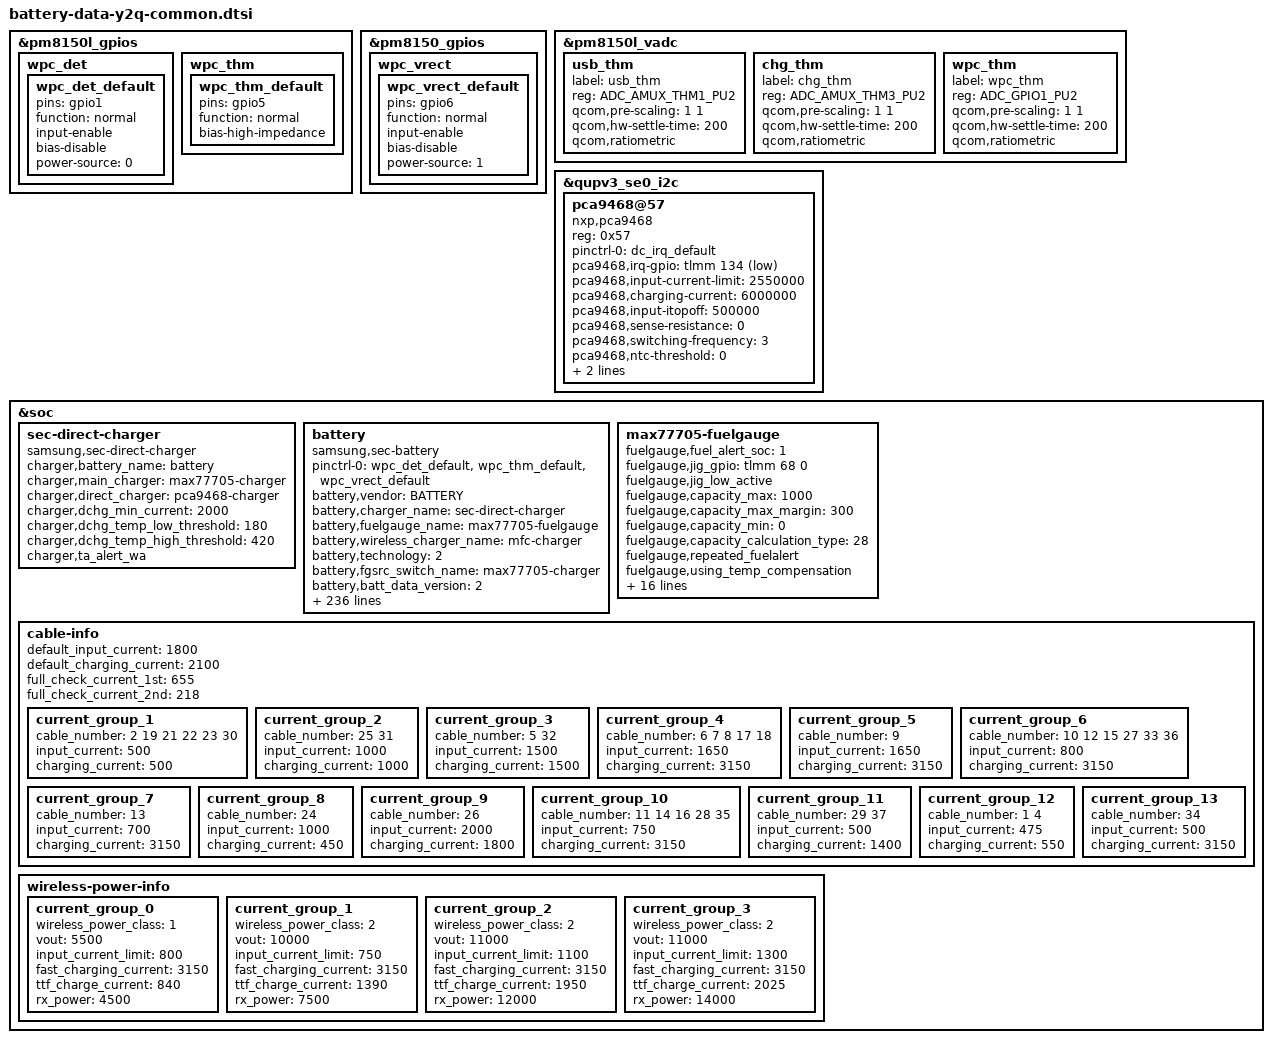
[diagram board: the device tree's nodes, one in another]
/* Copyright (c) 2014, The Linux Foundation. All rights reserved.
 *
 * This program is free software; you can redistribute it and/or modify
 * it under the terms of the GNU General Public License version 2 and
 * only version 2 as published by the Free Software Foundation.
 *
 * This program is distributed in the hope that it will be useful,
 * but WITHOUT ANY WARRANTY; without even the implied warranty of
 * MERCHANTABILITY or FITNESS FOR A PARTICULAR PURPOSE.  See the
 * GNU General Public License for more details.
 */

#include "battery-rx-data-y2q-idt.dtsi"

&pm8150l_gpios {
	wpc_det { /* WPC_DET */
		wpc_det_default: wpc_det_default {
			pins = "gpio1";
			function = "normal";
			input-enable;
			bias-disable;
			power-source = <0>;
		};
	};
	wpc_thm { /* GPIO_05 */
		wpc_thm_default: wpc_thm_default {
			pins = "gpio5";
			function = "normal";
			bias-high-impedance;
		};
	};
};

&pm8150_gpios {
    wpc_vrect { /* VRECT_INT */
        wpc_vrect_default: wpc_vrect_default {
            pins = "gpio6";
            function = "normal";
            input-enable;
            bias-disable;
            power-source = <1>;
        };
    };
};

&pm8150l_vadc {
	usb_thm { /* AMUX_1 */
		label = "usb_thm";
		reg = <ADC_AMUX_THM1_PU2>;
		qcom,pre-scaling = <1 1>;
		qcom,hw-settle-time = <200>;
		qcom,ratiometric;
	};
	chg_thm { /* AMUX_3 */
		label = "chg_thm";
		reg = <ADC_AMUX_THM3_PU2>;
		qcom,pre-scaling = <1 1>;
		qcom,hw-settle-time = <200>;
		qcom,ratiometric;
	};
	wpc_thm { /* GPIO_05 */
		label = "wpc_thm";
		reg = <ADC_GPIO1_PU2>;
		qcom,pre-scaling = <1 1>;
		qcom,hw-settle-time = <200>;
		qcom,ratiometric;
	};
};

&qupv3_se0_i2c {
	status = "okay";

	pca9468@57 {
		compatible = "nxp,pca9468";
		reg = <0x57>;
		pinctrl-names = "default";
		pinctrl-0 = <&dc_irq_default>;

		pca9468,irq-gpio = <&tlmm 134 GPIO_ACTIVE_LOW>; /* DC_IRQ */
		pca9468,input-current-limit = <2550000>; /* 2.55A */
		pca9468,charging-current = <6000000>; /* 6A */
		pca9468,input-itopoff = <500000>; /* 500mA */
		pca9468,sense-resistance = <0>; /* 5mOhm */
		pca9468,switching-frequency = <3>; /* 980KHz */
		pca9468,ntc-threshold = <0>; /* disable */
		pca9468,chg_gpio_en = <&tlmm 173 0>; /* DC_CPEN */
		pca9468,ta-mode = <1>; /* 2:1 charging mode */
	};
};

&soc {
	sec-direct-charger {
		status = "okay";
		compatible = "samsung,sec-direct-charger";

		charger,battery_name = "battery";
		charger,main_charger = "max77705-charger";
		charger,direct_charger = "pca9468-charger";

		charger,dchg_min_current = <2000>;
		charger,dchg_temp_low_threshold = <180>;
		charger,dchg_temp_high_threshold = <420>;

		charger,ta_alert_wa;
	};

	battery {
		status = "okay";
		compatible = "samsung,sec-battery";
		pinctrl-names = "default";
		pinctrl-0 = <&wpc_det_default &wpc_thm_default &wpc_vrect_default>;
		battery,vendor = "BATTERY";
		battery,charger_name = "sec-direct-charger";
		battery,fuelgauge_name = "max77705-fuelgauge";
		battery,wireless_charger_name = "mfc-charger";
		battery,technology = <2>; /* POWER_SUPPLY_TECHNOLOGY_LION */
		battery,fgsrc_switch_name = "max77705-charger"; /* Fuelgauge voltage source */

		battery,batt_data_version = <2>;

		battery,chip_vendor = "QCOM";
		battery,temp_adc_type = <1>; /* SEC_BATTERY_ADC_TYPE_AP */

		battery,temp_check_type = <1>; /* SEC_BATTERY_TEMP_CHECK_ADC */
		battery,usb_temp_check_type = <1>;
		battery,chg_temp_check_type = <1>;
		battery,wpc_temp_check_type = <1>;
		battery,dchg_temp_check_type = <1>;

		battery,thermal_source = <2>; /* SEC_BATTERY_THERMAL_SOURCE_ADC */
		battery,usb_thermal_source = <2>; /* SEC_BATTERY_THERMAL_SOURCE_ADC */
		battery,chg_thermal_source = <2>; /* SEC_BATTERY_THERMAL_SOURCE_ADC */
		battery,wpc_thermal_source = <2>; /* SEC_BATTERY_THERMAL_SOURCE_ADC */
		battery,dchg_thermal_source = <3>; /* SEC_BATTERY_THERMAL_SOURCE_CHG_ADC */

		battery,polling_time = <10 30 30 30 3600>;

		battery,temp_table_adc = <138199 161533 186995 214402 249134
						288847 341868 396892 460726 535005
						615065 704397 800865 899552 1008268
						1121431 1232583 1338104 1426520 1514907
						1587874 1647527 1699531>;
		battery,temp_table_data = <900 850 800 750 700
						650 600 550 500 450
						400 350 300 250 200
						150 100 50 0 (-50)
						(-100) (-150) (-200)>;

		battery,usb_temp_table_adc = <239676 280124 326167 374869 432677
						499761 573557 652248 738271 833167
						926469 1023081 1121431 1216356 1309450
						1399286 1479339 1549891 1607057 1657965
						1699401 1731119 1757114>;
		battery,usb_temp_table_data = <900 850 800 750 700
						650 600 550 500 450
						400 350 300 250 200
						150 100 50 0 (-50)
						(-100) (-150) (-200)>;

		battery,chg_temp_table_adc = <111317 134709 158549 185834 216586
						253719 307006 362355 426347 494585
						582842 670883 766096 866897 971806
						1080427 1188285 1297663 1388249 1478597
						1559760 1617754 1672663>;
		battery,chg_temp_table_data = <900 850 800 750 700
						650 600 550 500 450
						400 350 300 250 200
						150 100 50 0 (-50)
						(-100) (-150) (-200)>;

		battery,wpc_temp_table_adc = <138199 161533 186995 214402 249134
						288847 341868 396892 460726 535005
						615065 704397 800865 899552 1008268
						1121431 1232583 1338104 1426520 1514907
						1587874 1647527 1699531>;
		battery,wpc_temp_table_data = <900 850 800 750 700
						650 600 550 500 450
						400 350 300 250 200
						150 100 50 0 (-50)
						(-100) (-150) (-200)>;

		battery,dchg_temp_table_adc = <98532 119646 143106 170476 195500
						229908 281520 333914 394910 459034
						542708 624036 722568 821882 920414
						1024420 1120606 1229304 1320798 1406818
						1493620 1546014 1599190>;
		battery,dchg_temp_table_data = <900 850 800 750 700
						650 600 550 500 450
						400 350 300 250 200
						150 100 50 0 (-50)
						(-100) (-150) (-200)>;

		battery,wireless_cc_cv = <85>;
		battery,wpc_det = <&pm8150l_gpios 1 GPIO_ACTIVE_HIGH>; /* WPC_DET */
		battery,wpc_en = <&tlmm 127 0>; /* WPC_EN */
		battery,mst_pwr_en = <&tlmm 151 0>; /* MST_PWR_EN */
		battery,adc_check_count = <5>;

		battery,cable_check_type = <4>; /* SEC_BATTERY_CABLE_CHECK_PSY */
		battery,cable_source_type = <1>; /* SEC_BATTERY_CABLE_SOURCE_EXTERNAL */
		battery,polling_type = <1>; /* SEC_BATTERY_MONITOR_ALARM */
		battery,monitor_initial_count = <0>;

		battery,battery_check_type = <0>; /* SEC_BATTERY_CHECK_NONE */
		battery,check_count = <0>;
		battery,check_adc_max = <1440>;
		battery,check_adc_min = <0>;

		battery,ovp_uvlo_check_type = <3>; /* SEC_BATTERY_OVP_UVLO_CHGPOLLING */

		battery,temp_check_count = <1>;
		battery,temp_highlimit_threshold_event = <700>;
		battery,temp_highlimit_recovery_event = <680>;
		battery,temp_high_threshold_event = <500>;
		battery,temp_high_recovery_event = <480>;
		battery,temp_low_threshold_event = <0>;
		battery,temp_low_recovery_event = <20>;
		battery,temp_highlimit_threshold_normal = <700>;
		battery,temp_highlimit_recovery_normal = <680>;
		battery,temp_high_threshold_normal = <500>;
		battery,temp_high_recovery_normal = <480>;
		battery,temp_low_threshold_normal = <0>;
		battery,temp_low_recovery_normal = <20>;
		battery,temp_highlimit_threshold_lpm = <700>;
		battery,temp_highlimit_recovery_lpm = <680>;
		battery,temp_high_threshold_lpm = <500>;
		battery,temp_high_recovery_lpm = <480>;
		battery,temp_low_threshold_lpm = <0>;
		battery,temp_low_recovery_lpm = <20>;
		battery,wpc_high_threshold_normal = <450>;
		battery,wpc_high_recovery_normal = <430>;
		battery,wpc_low_threshold_normal = <0>;
		battery,wpc_low_recovery_normal = <20>;
		battery,tx_high_threshold = <450>;
		battery,tx_high_recovery = <400>;
		battery,tx_low_threshold = <0>;
		battery,tx_low_recovery = <50>;
		battery,full_check_type = <2>; /* SEC_BATTERY_FULLCHARGED_FG_CURRENT */
		battery,full_check_type_2nd = <2>; /* SEC_BATTERY_FULLCHARGED_FG_CURRENT */
		battery,full_check_count = <1>;
		battery,chg_gpio_full_check = <0>;
		battery,chg_polarity_full_check = <1>;

		battery,chg_high_temp = <450>;
		battery,chg_high_temp_recovery = <430>;
		battery,dchg_high_temp = <500>;
		battery,dchg_high_temp_recovery = <440>;
		battery,dchg_high_batt_temp = <400>;
		battery,dchg_high_batt_temp_recovery = <380>;
		battery,chg_input_limit_current = <1000>;
		battery,chg_charging_limit_current = <1900>;
		battery,dchg_input_limit_current = <1000>;
		battery,dchg_charging_limit_current = <2000>;

		battery,charging_limit_by_tx_check = <1>;
		battery,charging_limit_current_by_tx = <1100>;

		battery,wpc_temp_control_source = <1>; /* TEMP_CONTROL_SOURCE_BAT_THM = WPC_THM */
		battery,wpc_high_temp = <400>;
		battery,wpc_high_temp_recovery = <380>;
		battery,wpc_input_limit_current = <600>;
		battery,wpc_charging_limit_current = <3150>;
		battery,wpc_temp_lcd_on_control_source = <1>; /* TEMP_CONTROL_SOURCE_BAT_THM = WPC_THM */
		battery,wpc_lcd_on_high_temp = <400>;
		battery,wpc_lcd_on_high_temp_rec = <380>;
		battery,wpc_lcd_on_input_limit_current = <450>;

		battery,wpc_store_high_temp = <360>;
		battery,wpc_store_high_temp_recovery = <340>;
		battery,wpc_store_charging_limit_current = <400>;
		battery,wpc_store_lcd_on_high_temp = <360>;
		battery,wpc_store_lcd_on_high_temp_rec = <300>;
		battery,wpc_store_lcd_on_charging_limit_current = <400>;
		battery,store_mode_buckoff;

		battery,ta_alert_wa;

		battery,sleep_mode_limit_current = <800>;
		battery,wc_full_input_limit_current = <100>;

		battery,mix_high_temp = <420>;
		battery,mix_high_chg_temp = <500>;
		battery,mix_high_temp_recovery = <390>;

		/* SEC_BATTERY_FULL_CONDITION_NOTIMEFULL | SEC_BATTERY_FULL_CONDITION_VCELL */
		battery,full_condition_type = <9>;
		battery,full_condition_soc = <93>;
		battery,full_condition_vcell = <4330>;

		battery,recharge_check_count = <1>;
		battery,recharge_condition_type = <4>; /* SEC_BATTERY_RECHARGE_CONDITION_VCELL */
		battery,recharge_condition_soc = <98>;
		battery,recharge_condition_vcell = <4310>;

		battery,charging_total_time = <14400>;
		battery,hv_charging_total_time = <10800>;
		battery,normal_charging_total_time = <18000>;
		battery,usb_charging_total_time = <36000>;
		battery,recharging_total_time = <5400>;
		battery,charging_reset_time = <0>;

		battery,chg_float_voltage = <4380>;
		battery,chg_ocp_current = <6200>;
		battery,chg_ocp_dtc = <100>;

		battery,pre_afc_work_delay = <2000>;
		battery,pre_wc_afc_work_delay = <4000>;
		battery,pre_afc_input_current = <500>;
		battery,pre_wc_afc_input_current = <500>;
		battery,prepare_ta_delay = <0>; /* msec */

		battery,swelling_high_temp_block = <420>;
		battery,swelling_high_temp_recov = <400>;
		battery,swelling_wc_high_temp_block = <420>;
		battery,swelling_wc_high_temp_recov = <400>;
		battery,swelling_low_temp_block_1st = <150>;
		battery,swelling_low_temp_recov_1st = <170>;
		battery,swelling_low_temp_block_2nd = <50>;
		battery,swelling_low_temp_recov_2nd = <70>;
		battery,swelling_low_temp_3rd_ctrl;
		battery,swelling_low_temp_block_3rd = <180>;
		battery,swelling_low_temp_recov_3rd = <200>;

		battery,swelling_low_temp_current = <1000>;	/* 0.24C */
		battery,swelling_low_temp_current_2nd = <400>;	/* 0.1C */
		battery,swelling_low_temp_current_3rd = <3100>;	/* 0.72C */
		battery,swelling_low_temp_topoff = <218>;	/* 0.05C */
		battery,swelling_high_temp_current = <1550>;	/* 0.36C */
		battery,swelling_high_temp_topoff = <218>;	/* 0.05C */
		battery,swelling_wc_high_temp_current = <1000>;	/* 0.24C */
		battery,swelling_wc_low_temp_current = <1000>;	/* 0.24C */
		battery,swelling_wc_low_temp_current_2nd = <400>;	/* 0.1C */
		battery,swelling_wc_low_temp_current_3rd = <3100>;	/* 0.72C */

		battery,swelling_drop_float_voltage = <4150>;
		battery,swelling_high_rechg_voltage = <4000>;
		battery,swelling_low_rechg_thr = <180>;

		battery,siop_input_limit_current = <1200>;
		battery,siop_charging_limit_current = <1800>;
		battery,siop_hv_input_limit_current = <700>;
		battery,siop_hv_input_limit_current_2nd = <450>;
		battery,siop_hv_charging_limit_current = <1000>;
		battery,siop_apdo_input_limit_current = <1000>;
		battery,siop_apdo_charging_limit_current = <2000>;

		battery,siop_wireless_input_limit_current = <700>;
		battery,siop_wireless_charging_limit_current = <700>;
		battery,siop_hv_wireless_input_limit_current = <700>;
		battery,siop_hv_wireless_charging_limit_current = <700>;
		battery,siop_store_hv_wireless_input_limit_current = <450>;

		battery,wireless_otg_input_current = <900>;

		battery,ttf_hv_charge_current = <2625>;
		battery,ttf_hv_wireless_charge_current = <1390>;
		battery,ttf_wireless_charge_current = <840>;
		battery,ttf_dc25_charge_current = <4000>;

		battery,rp_current_rp1 = <500>;
		battery,rp_current_rp2 = <1500>;
		battery,rp_current_rp3 = <3000>;
		battery,rp_current_rdu_rp3 = <2100>;
		battery,rp_current_abnormal_rp3 = <1800>;

		battery,pd_charging_charge_power = <15000>;
		battery,max_charging_current = <3150>;
		battery,max_charging_charge_power = <25000>; /* 25W */

		/* cycle, chg_float_voltage, recharge_condition_vcell, full_condition_vcell, full_condition_soc, step charging condition */
		battery,age_data = <0 4380 4310 4330 93
				300 4360 4290 4310 92
				400 4340 4270 4290 91
				700 4320 4250 4270 90
				1000 4270 4200 4220 89>;

		battery,health_condition = <
			/* CYCLE ASOC */
			900 75	/* GOOD */
			1200 65 /* NORMAL */
			1500 55 /* AGED */
			>;

		/* step charging option */
		battery,step_charging_type = <0>;

		/* direct step charging option */
		battery,dc_step_chg_type = <0x6B>;
		battery,dc_step_chg_charge_power = <22000>;
		battery,dc_step_chg_step = <3>;
		battery,dc_step_chg_cond_vol = <4125 4250 4380>; /*<25w 3step> STEP_CHARGING_CONDITION_VOLTAGE */ 
		battery,dc_step_chg_cond_iin = <2045 1835 0>; /* <25w 3step> STEP_CHARGING_CONDITION_INPUT_CURRENT */
		battery,dc_step_chg_iin_check_cnt = <3>;
		battery,dc_step_chg_cond_soc = <35 60 100
										35 60 100
										35 60 100
										35 60 100
										35 60 100>; /* <25w 3step> STEP_CHARGING_CONDITION_SOC */
		battery,dc_step_chg_val_vfloat = <4125 4250 4380>; /* <25w 3step> STEP_CHARGING_CONDITION_FLOAT_VOLTAGE */
		battery,dc_step_chg_val_iout = <5290 4090 3670>; /* <25w 3step> */


		battery,snkcap_data = /bits/ 8 <0x04 0x2C 0x91 0x01 0x36 0xC8 0xD0 0x02 0x00 0xC8 0x90
								0x41 0x8B 0x35 0x21 0xDC 0xC0>;


		battery,max_input_voltage = <9000>; /* mV */
		battery,max_input_current = <3000>; /* mA */

		battery,enable_sysovlo_irq;
		battery,enable_noise_wa;
		battery,dis_auto_shipmode_temp_ctrl;

		battery,standard_curr = <3150>;
		battery,expired_time = <10800>;
		battery,recharging_expired_time = <5400>;

		battery,battery_full_capacity = <4500>;
		battery,cisd_max_voltage_thr = <4430>; /* batttery ovp dettection voltage */
		battery,cisd_alg_index = <8>;
		battery,ignore_cisd_index = <0 0>;
		battery,ignore_cisd_index_d = <0 80>; /* Do not use AFC_FAIL_PER_DAY to DROP_VALUE_PER_DAY */ 

		battery,tx_stop_capacity = <30>;
		battery,tx_minduty_default = <20>;
		battery,tx_minduty_5V = <50>;

		battery,tx_uno_vout = <5>; /* WC_TX_VOUT_7_5V */
		battery,tx_gear_vout = <0>; /* WC_TX_VOUT_5_0V */
		battery,tx_uno_iout = <1500>;
		battery,tx_mfc_iout_gear = <1500>;
		battery,tx_mfc_iout_phone = <1100>;
		battery,tx_mfc_iout_phone_5v = <300>;
		battery,tx_mfc_iout_lcd_on = <900>;

		battery,batt_temp_adj_gap_inc = <100>;
		battery,batt_temp_adj_gap_dec = <100>;
		/* battery,fake_capacity; */

		battery,support_unknown_wpcthm;

		io-channels = <&pm8150l_vadc ADC_GPIO1_PU2>, <&pm8150l_vadc ADC_AMUX_THM3_PU2>, <&pm8150l_vadc ADC_GPIO1_PU2>, <&pm8150l_vadc ADC_AMUX_THM1_PU2>;
		io-channel-names = "adc-temp", "adc-chg-temp", "adc-wpc-temp", "adc-usb-temp";
	};

	max77705-fuelgauge {
		/* for 4500mAh battery */
		status = "okay";
		fuelgauge,fuel_alert_soc = <1>;
		fuelgauge,jig_gpio = <&tlmm 68 0>; /* IFC_SENSE_INT_AP */
		fuelgauge,jig_low_active;
		fuelgauge,capacity_max = <1000>;
		fuelgauge,capacity_max_margin = <300>;
		fuelgauge,capacity_min = <0>;
		fuelgauge,capacity_calculation_type = <28>;
		fuelgauge,repeated_fuelalert;
		fuelgauge,using_temp_compensation;
		fuelgauge,low_temp_limit = <100>;
		fuelgauge,using_hw_vempty;
		fuelgauge,v_empty = <0xA7E2>; /* Empty: 3350mV, Recover: 3920mV */
		fuelgauge,v_empty_origin = <0x7D54>; /* Empty: 2500mV, Recover: 3360mV */
		fuelgauge,sw_v_empty_voltage = <3200>;
		fuelgauge,sw_v_empty_voltage_cisd = <3100>;
		fuelgauge,sw_v_empty_recover_voltage = <3480>;
		fuelgauge,fg_resistor = <2>;
		fuelgauge,capacity = <0x0FEF>; /* capacity = fullcapnom = DesignCap */
		fuelgauge,fg_reset_wa_data = <0x0FEF 0x3200 0x03FB 0x0034 0x2534>; /* fullcapnom(=capacity), dPacc, dQacc,  rcomp0, tempco */
		fuelgauge,discharge_temp_threshold = <600>;
		fuelgauge,discharge_volt_threshold = <4200>;
		fuelgauge,ttf_capacity = <3625>;
		fuelgauge,cv_data = <
			3733	840	1462
			3616	847	1432
			3575	849	1421
			3452	853	1401
			3342	860	1370
			3228	864	1350
			3133	866	1340
			3019	874	1299
			2929	879	1268
			2843	883	1247
			2754	887	1227
			2625	895	1176
			2531	898	1155
			2410	905	1114
			2348	908	1094
			2214	915	1043
			2103	920	1002
			2019	924	971
			1911	930	920
			1834	933	899
			1722	942	817
			1649	946	776
			1532	950	735
			1410	958	643
			1338	960	623
			1213	969	510
			1105	975	428
			1010	983	305
			955	988	223
			881	990	123
			864	996	113
			761	1000	103
			710	1000	51
			668	1000	0
		>;
	};

/* sec_battery_cable
 *   0	UNKNOWN,
 *   1	NONE,
 *   2	PREPARE_TA,
 *   3	TA,
 *   4	USB,
 *   5	USB_CDP,
 *   6	9V_TA,
 *   7	9V_ERR,
 *   8	9V_UNKNOWN,
 *   9	12V_TA,
 *  10	WIRELESS,
 *  11	HV_WIRELESS,
 *  12	PMA_WIRELESS,
 *  13	WIRELESS_PACK,
 *  14	CABLE_WIRELESS_HV_PACK,
 *  15	WIRELESS_STAND,
 *  16	WIRELESS_HV_STAND,
 *  17	QC20,
 *  18	QC30,
 *  19	PDIC,
 *  20	UARTOFF,
 *  21	OTG,
 *  22	LAN_HUB,
 *  23	POWER_SHARING,
 *  24	HMT_CONNECTED,
 *  25	HMT_CHARGE,
 *  26	HV_TA_CHG_LIMIT,
 *  27	WIRELESS_VEHICLE,
 *  28	WIRELESS_HV_VEHICLE,
 *  29	PREPARE_WIRELESS_HV,
 *  30  TIMEOUT,
 *  31  SMART_OTG,
 *  32  SMART_NOTG,
 *  33  WIRELESS_TX,
 *  34	HV_WIRELESS_20,
 *  35	HV_WIRELESS_20_LIMIT,
 *  36	WIRELESS_FAKE,
 *  37  PREPARE_WIRELESS_20,
 *  38	CABLE_PDIC_APDO,
 *  39	CABLE_MAX,
 */
	cable-info {
		default_input_current = <1800>;
		default_charging_current = <2100>;
		full_check_current_1st = <655>;
		full_check_current_2nd = <218>;

		current_group_1 {
			cable_number = <2 19 21 22 23 30>;
			input_current = <500>;
			charging_current = <500>;
		};
		current_group_2 {
			cable_number = <25 31>;
			input_current = <1000>;
			charging_current = <1000>;
		};
		current_group_3 {
			cable_number = <5 32>;
			input_current = <1500>;
			charging_current = <1500>;
		};
		current_group_4 {
			cable_number = <6 7 8 17 18>;
			input_current = <1650>;
			charging_current = <3150>;
		};
		current_group_5 {
			cable_number = <9>;
			input_current = <1650>;
			charging_current = <3150>;
		};
		current_group_6 {
			cable_number = <10 12 15 27 33 36>;
			input_current = <800>;
			charging_current = <3150>;
		};
		current_group_7 {
			cable_number = <13>;
			input_current = <700>;
			charging_current = <3150>;
		};
		current_group_8 {
			cable_number = <24>;
			input_current = <1000>;
			charging_current = <450>;
		};
		current_group_9 {
			cable_number = <26>;
			input_current = <2000>;
			charging_current = <1800>;
		};
		current_group_10 {
			cable_number = <11 14 16 28 35>;
			input_current = <750>;
			charging_current = <3150>;
		};
		current_group_11 {
			cable_number = <29 37>;
			input_current = <500>;
			charging_current = <1400>;
		};
		current_group_12 {
			cable_number = <1 4>;
			input_current = <475>;
			charging_current = <550>;
		};
		current_group_13 {
			cable_number = <34>;
			input_current = <500>;
			charging_current = <3150>;
		};
	};
	wireless-power-info {
		current_group_0 {
			wireless_power_class = <1>;
			vout = <5500>;
			input_current_limit = <800>;
			fast_charging_current = <3150>;
			ttf_charge_current = <840>;
			rx_power = <4500>;
		};
		current_group_1 {
			wireless_power_class = <2>;
			vout = <10000>;
			input_current_limit = <750>;
			fast_charging_current = <3150>;
			ttf_charge_current = <1390>;
			rx_power = <7500>;
		};
		current_group_2 {
			wireless_power_class = <2>;
			vout = <11000>;
			input_current_limit = <1100>;
			fast_charging_current = <3150>;
			ttf_charge_current = <1950>;
			rx_power = <12000>;
		};
		current_group_3 {
			wireless_power_class = <2>;
			vout = <11000>;
			input_current_limit = <1300>;
			fast_charging_current = <3150>;
			ttf_charge_current = <2025>;
			rx_power = <14000>;
		};
	};
};
